# va416xx register map
Vendor: VORAGO TECHNOLOGIES; Series: M4; File version: 1.3
CPU: CM4 r0p1, little endian, no MPU, FPU, 4 interrupt priority bits
Registers are 32-bit, read-write, reset 0x0 unless marked. A register's access mark holds for its fields unless they carry their own. Offsets are from the block's base; [hi:lo] are bit positions; {n}, {i} and the like mark numbered series; <NAME> marks a mode.

## PORTA — GPIO Peripheral
Base 0x40012000
Same registers: PORTB 0x40012400, PORTC 0x40012800, PORTD 0x40012C00, PORTE 0x40013000, PORTF 0x40013400, PORTG 0x40013800
0x00 DATAIN ro
{0x0+i} DATAINBYTE[{i}] (i=0..3) 8-bit ro (alternate view of DATAIN) — Data In Register by Byte
0x04 DATAINRAW ro
0x04 DATAINRAWBYTE[%s] 8-bit ro (alternate view of DATAINRAW) — Data In Raw Register by Byte
0x08 DATAOUT wo
{0x8+i} DATAOUTBYTE[{i}] (i=0..3) 8-bit wo (alternate view of DATAOUT) — Data Out Register by Byte
0x0C DATAOUTRAW wo — Data Out Register
0x0C DATAOUTRAWBYTE[%s] 8-bit wo (alternate view of DATAOUTRAW) — Data Out Register by Byte
0x10 SETOUT wo
0x10 SETOUTBYTE[%s] 8-bit wo (alternate view of SETOUT) — Set Out Register by Byte
0x14 CLROUT wo — Clear Out Register
0x14 CLROUTBYTE[%s] 8-bit wo (alternate view of CLROUT) — Clear Out Register by Byte
0x18 TOGOUT wo — Toggle Out Register
0x18 TOGOUTBYTE[%s] 8-bit wo (alternate view of TOGOUT) — Toggle Out Register by Byte
0x1C DATAMASK
{0x1C+i} DATAMASKBYTE[{i}] (i=0..3) 8-bit (alternate view of DATAMASK) — Data Out Register by Byte
0x20 DIR — Direction Register (1:Output, 0:Input)
0x20 DIRBYTE[%s] 8-bit (alternate view of DIR) — Direction Register by Byte
0x24 PULSE — Pulse Mode Register
0x24 PULSEBYTE[%s] 8-bit (alternate view of PULSE) — Pulse Mode Register by Byte
0x28 PULSEBASE — Pulse Base Value Register
0x28 PULSEBASEBYTE[%s] 8-bit (alternate view of PULSEBASE) — Pulse Base Mode Register by Byte
0x2C DELAY1
0x2C DELAY1BYTE[%s] 8-bit (alternate view of DELAY1) — Delay1 Register by Byte
0x30 DELAY2
0x30 DELAY2BYTE[%s] 8-bit (alternate view of DELAY2) — Delay2 Register by Byte
0x34 IRQ_SEN — Interrupt Sense Register (1:Level Sensitive, 0:Edge Sensitive)
0x38 IRQ_EDGE — Interrupt Both Edge Register (1:Both Edges, 0:Single Edge)
0x3C IRQ_EVT — Interrupt Event Register (1:HighLevel/L->H Edge, 0:LowLevel/H->L Edge)
0x40 IRQ_ENB — Interrupt Enable Register
0x44 IRQ_RAW ro — Raw Interrupt Status
0x48 IRQ_END ro — Masked Interrupt Status
0x4C EDGE_STATUS
0x3FC PERID ro reset 0x21007E9 — Peripheral ID Register

## TIM0 — Timer/Counter Peripheral
Base 0x40018000
Same registers: TIM{n} {0x40018000+0x400*n} (n=1..15), TIM{n} {0x40024000+0x400*n} (n=16..23)
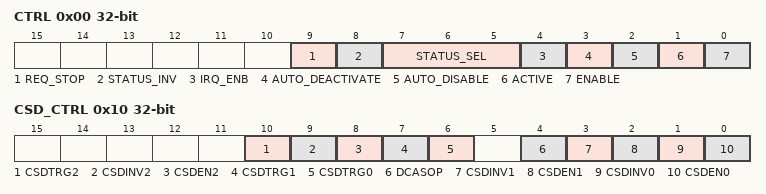
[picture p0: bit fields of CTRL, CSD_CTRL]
0x00 CTRL — Control Register
  [9] REQ_STOP — Stop Request
  [8] STATUS_INV — Invert the Output Status
  [7:5] STATUS_SEL — Counter Status Selection
    0=DONE (Single cycle pulse when the counter reaches 0); 1=ACTIVE (Returns the counter ACTIVE bit); 2=TOGGLE (Toggles the STATUS bit everytime the counter reaches 0. Basically a divide by 2 counter output.); 3=PWMA (Selects the Pulse Width Modulated output. It 1 when the counter value is >= the PWMA_VALUE); 4=PWMB (Selects the Pulse Width Modulated output. It 1 when the counter value is < the PWMA_VALUE and value is > PWMA_VALUE); 5=ENABLED (Returns the counter ENABLED bit); 6=PWMA_ACTIVE (Selects the Pulse Width Modulated output. It 1 when the counter value is <= the PWMA_VALUE and value is >= 0)
  [4] IRQ_ENB — Interrupt Enable
  [3] AUTO_DEACTIVATE — Auto Deactivate the counter (set ACTIVE to 0) when the count reaches 0
  [2] AUTO_DISABLE — Auto Disables the counter (set ENABLE to 0) when the count reaches 0
  [1] ACTIVE ro — Counter Active
  [0] ENABLE — Counter Enable
0x04 RST_VALUE — The value that counter start from after reaching 0.
0x08 CNT_VALUE — The current value of the counter
0x0C ENABLE — Alternate access to the Counter ENABLE bit in the CTRL Register
  [0] ENABLE — Counter Enable
0x10 CSD_CTRL — The Cascade Control Register. Controls the counter external enable signals
  [10] CSDTRG2 — Cascade 2 Trigger mode
  [9] CSDINV2 — Cascade 2 Invert
  [8] CSDEN2 — Cascade 2 Enable
  [7] CSDTRG1 — Cascade 1 Enabled as Trigger
  [6] CSDTRG0 — Cascade 0 Enabled as Trigger
  [4] DCASOP — Dual Cascade Operation (0:AND, 1:OR)
  [3] CSDINV1 — Cascade 1 Invert
  [2] CSDEN1 — Cascade 1 Enable
  [1] CSDINV0 — Cascade 0 Invert
  [0] CSDEN0 — Cascade 0 Enable
{0x14+4i} CASCADE{i} (i=0..2) — Cascade Enable Selection
  [7:0] CASSEL — Cascade Selection
0x20 PWM_VALUE — The Pulse Width Modulation Value
0x20 PWMA_VALUE (alternate view of PWM_VALUE) — The Pulse Width Modulation ValueA
0x24 PWMB_VALUE — The Pulse Width Modulation ValueB
0x3FC PERID ro reset 0x21107E9 — Peripheral ID Register
